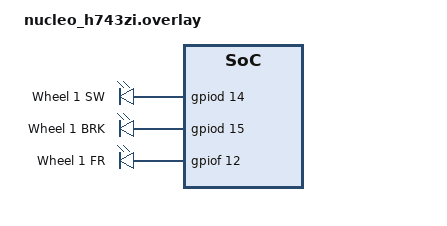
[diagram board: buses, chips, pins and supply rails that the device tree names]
/ {
    leds {
        w_1_sw: wheel_1_sw { // D10 TODO: PWM
            gpios = <&gpiod 14 GPIO_ACTIVE_HIGH>;
            label = "Wheel 1 SW";
        };
        w_1_brk: wheel_1_brk { // D9
            gpios = <&gpiod 15 GPIO_ACTIVE_HIGH>;
            label = "Wheel 1 BRK";
        };
        w_1_fr: wheel_1_fr { // D8
            gpios = <&gpiof 12 GPIO_ACTIVE_HIGH>;
            label = "Wheel 1 FR";
        };
    };
    aliases {
        wheel1-sw = &w_1_sw;
        wheel1-brk = &w_1_brk;
        wheel1-fr = &w_1_fr;
    };
};
